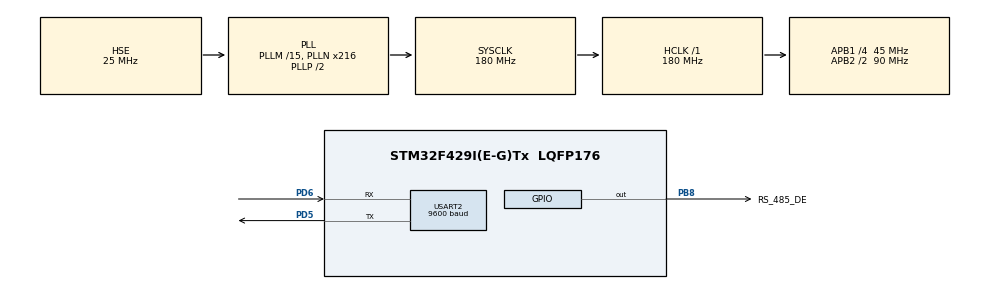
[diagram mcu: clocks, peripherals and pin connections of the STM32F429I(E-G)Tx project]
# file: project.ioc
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Mcu.Family=STM32F4
Mcu.Name=STM32F429I(E-G)Tx
Mcu.Package=LQFP176
NVIC.PriorityGroup=NVIC_PRIORITYGROUP_4
NVIC.TIM7_IRQn=true\:0\:0\:false\:false\:true\:false\:true
NVIC.TimeBase=TIM7_IRQn
NVIC.TimeBaseIP=TIM7
NVIC.USART2_IRQn=true\:0\:0\:false\:false\:true\:true\:false
PA13.Mode=Serial_Wire
PA13.Signal=SYS_JTMS-SWDIO
PA14.Mode=Serial_Wire
PA14.Signal=SYS_JTCK-SWCLK
PB8.GPIO_Label=RS_485_DE
PB8.GPIO_PuPd=GPIO_PULLDOWN
PB8.Signal=GPIO_Output
PC14/OSC32_IN.Mode=LSE-External-Oscillator
PC14/OSC32_IN.Signal=RCC_OSC32_IN
PC15/OSC32_OUT.Mode=LSE-External-Oscillator
PC15/OSC32_OUT.Signal=RCC_OSC32_OUT
PD5.Mode=Asynchronous
PD5.Signal=USART2_TX
PD6.Mode=Asynchronous
PD6.Signal=USART2_RX
PH0/OSC_IN.Mode=HSE-External-Oscillator
PH0/OSC_IN.Signal=RCC_OSC_IN
PH1/OSC_OUT.Mode=HSE-External-Oscillator
PH1/OSC_OUT.Signal=RCC_OSC_OUT
ProjectManager.HeapSize=0x1500
ProjectManager.StackSize=0x2000
ProjectManager.TargetToolchain=MDK-ARM V5
RCC.48MHZClocksFreq_Value=90000000
RCC.AHBFreq_Value=180000000
RCC.APB1CLKDivider=RCC_HCLK_DIV4
RCC.APB1Freq_Value=45000000
RCC.APB1TimFreq_Value=90000000
RCC.APB2CLKDivider=RCC_HCLK_DIV2
RCC.APB2Freq_Value=90000000
RCC.APB2TimFreq_Value=180000000
RCC.CortexFreq_Value=180000000
RCC.HCLKFreq_Value=180000000
RCC.HSE_VALUE=25000000
RCC.HSI_VALUE=16000000
RCC.PLLM=15
RCC.PLLN=216
RCC.PLLSourceVirtual=RCC_PLLSOURCE_HSE
RCC.SYSCLKFreq_VALUE=180000000
RCC.SYSCLKSource=RCC_SYSCLKSOURCE_PLLCLK
RCC.VCOOutputFreq_Value=360000000
USART2.BaudRate=9600
USART2.VirtualMode=VM_ASYNC
VP_SYS_VS_tim7.Mode=TIM7
board=custom

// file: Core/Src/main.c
/* USER CODE BEGIN Header */
/**
  ******************************************************************************
  * @file           : main.c
  * @brief          : Main program body
  ******************************************************************************
  * @attention
  *
  * <h2><center>&copy; Copyright (c) 2021 STMicroelectronics.
  * All rights reserved.</center></h2>
  *
  * This software component is licensed by ST under BSD 3-Clause license,
  * the "License"; You may not use this file except in compliance with the
  * License. You may obtain a copy of the License at:
  *                        opensource.org/licenses/BSD-3-Clause
  *
  ******************************************************************************
  */
/* USER CODE END Header */
#include "main.h"
#include "usart.h"
#include "gpio.h"

/* USER CODE BEGIN Includes */
#include "../../user_bsp/modbus/user_mb_slaves.h"
/* USER CODE END Includes */

void SystemClock_Config(void);

int main(void)
{

  /* MCU Configuration--------------------------------------------------------*/

  /* Reset of all peripherals, Initializes the Flash interface and the Systick. */
  HAL_Init();

  /* Configure the system clock */
  SystemClock_Config();

  /* Initialize all configured peripherals */
  MX_GPIO_Init();
  MX_USART2_UART_Init();
  /* USER CODE BEGIN 2 */
    HAL_GPIO_WritePin(RTUhandle.pRTU_DE_Port, RTUhandle.RTU_DE_Pin, GPIO_PIN_RESET);    //默认为接受模式

    __HAL_UART_ENABLE_IT(RTUhandle.pRTU_Usart, UART_IT_IDLE);//使能idle中断
    HAL_UART_Receive_IT(RTUhandle.pRTU_Usart, &RTUhandle.tmpReceiveBuf, 1);//打开串口接收
  /* USER CODE END 2 */

  /* Infinite loop */
    while (1)
    {

    /* USER CODE BEGIN 3 */

        if(RTUhandle.receiveFlagSts == MB_MSG_COM)
        {
            /* 解析数据帧 */
            RTU_Parse_Data();
            RTUhandle.receiveFlagSts  = MB_MSG_IDLE;

        }
    }

  /* USER CODE END 3 */
}

void SystemClock_Config(void)
{
  RCC_OscInitTypeDef RCC_OscInitStruct = {0};
  RCC_ClkInitTypeDef RCC_ClkInitStruct = {0};

  /** Configure the main internal regulator output voltage
  */
  __HAL_RCC_PWR_CLK_ENABLE();
  __HAL_PWR_VOLTAGESCALING_CONFIG(PWR_REGULATOR_VOLTAGE_SCALE1);
  /** Initializes the RCC Oscillators according to the specified parameters
  * in the RCC_OscInitTypeDef structure.
  */
  RCC_OscInitStruct.OscillatorType = RCC_OSCILLATORTYPE_HSE;
  RCC_OscInitStruct.HSEState = RCC_HSE_ON;
  RCC_OscInitStruct.PLL.PLLState = RCC_PLL_ON;
  RCC_OscInitStruct.PLL.PLLSource = RCC_PLLSOURCE_HSE;
  RCC_OscInitStruct.PLL.PLLM = 15;
  RCC_OscInitStruct.PLL.PLLN = 216;
  RCC_OscInitStruct.PLL.PLLP = RCC_PLLP_DIV2;
  RCC_OscInitStruct.PLL.PLLQ = 4;
  if (HAL_RCC_OscConfig(&RCC_OscInitStruct) != HAL_OK)
  {
    Error_Handler();
  }
  /** Activate the Over-Drive mode
  */
  if (HAL_PWREx_EnableOverDrive() != HAL_OK)
  {
    Error_Handler();
  }
  /** Initializes the CPU, AHB and APB buses clocks
  */
  RCC_ClkInitStruct.ClockType = RCC_CLOCKTYPE_HCLK|RCC_CLOCKTYPE_SYSCLK
                              |RCC_CLOCKTYPE_PCLK1|RCC_CLOCKTYPE_PCLK2;
  RCC_ClkInitStruct.SYSCLKSource = RCC_SYSCLKSOURCE_PLLCLK;
  RCC_ClkInitStruct.AHBCLKDivider = RCC_SYSCLK_DIV1;
  RCC_ClkInitStruct.APB1CLKDivider = RCC_HCLK_DIV4;
  RCC_ClkInitStruct.APB2CLKDivider = RCC_HCLK_DIV2;

  if (HAL_RCC_ClockConfig(&RCC_ClkInitStruct, FLASH_LATENCY_5) != HAL_OK)
  {
    Error_Handler();
  }
}

 /**
  * @brief  Period elapsed callback in non blocking mode
  * @note   This function is called  when TIM7 interrupt took place, inside
  * HAL_TIM_IRQHandler(). It makes a direct call to HAL_IncTick() to increment
  * a global variable "uwTick" used as application time base.
  * @param  htim : TIM handle
  * @retval None
  */
void HAL_TIM_PeriodElapsedCallback(TIM_HandleTypeDef *htim)
{
  if (htim->Instance == TIM7) {
    HAL_IncTick();
  }
}

void Error_Handler(void)
{
    __disable_irq();
    while (1)
    {
    }
}

/************************ (C) COPYRIGHT STMicroelectronics *****END OF FILE****/
